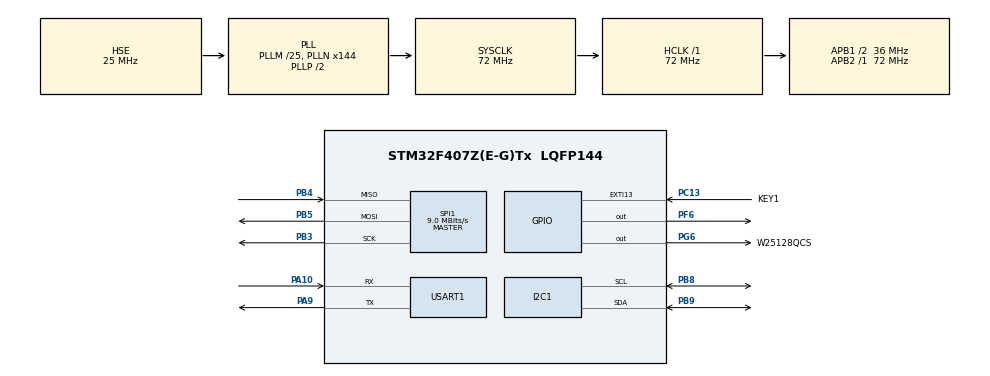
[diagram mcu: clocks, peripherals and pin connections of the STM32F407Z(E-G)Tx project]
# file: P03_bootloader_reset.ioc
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Mcu.Family=STM32F4
Mcu.Name=STM32F407Z(E-G)Tx
Mcu.Package=LQFP144
NVIC.EXTI15_10_IRQn=true\:4\:0\:true\:false\:true\:true\:true\:true
NVIC.PriorityGroup=NVIC_PRIORITYGROUP_4
NVIC.USART1_IRQn=true\:5\:0\:true\:false\:true\:true\:true\:true
PA10.Mode=Asynchronous
PA10.Signal=USART1_RX
PA13.Mode=Serial_Wire
PA13.Signal=SYS_JTMS-SWDIO
PA14.Mode=Serial_Wire
PA14.Signal=SYS_JTCK-SWCLK
PA9.Mode=Asynchronous
PA9.Signal=USART1_TX
PB3.Mode=Full_Duplex_Master
PB3.Signal=SPI1_SCK
PB4.Mode=Full_Duplex_Master
PB4.Signal=SPI1_MISO
PB5.Mode=Full_Duplex_Master
PB5.Signal=SPI1_MOSI
PB8.Mode=I2C
PB8.Signal=I2C1_SCL
PB9.Mode=I2C
PB9.Signal=I2C1_SDA
PC13-ANTI_TAMP.GPIO_Label=KEY1
PC13-ANTI_TAMP.GPIO_ModeDefaultEXTI=GPIO_MODE_IT_RISING
PC13-ANTI_TAMP.GPIO_PuPd=GPIO_PULLDOWN
PC13-ANTI_TAMP.Signal=GPXTI13
PC14-OSC32_IN.Mode=LSE-External-Oscillator
PC14-OSC32_IN.Signal=RCC_OSC32_IN
PC15-OSC32_OUT.Mode=LSE-External-Oscillator
PC15-OSC32_OUT.Signal=RCC_OSC32_OUT
PF6.GPIO_PuPd=GPIO_NOPULL
PF6.Signal=GPIO_Output
PG6.GPIO_Label=W25128QCS
PG6.GPIO_Speed=GPIO_SPEED_FREQ_HIGH
PG6.PinState=GPIO_PIN_SET
PG6.Signal=GPIO_Output
PH0-OSC_IN.Mode=HSE-External-Oscillator
PH0-OSC_IN.Signal=RCC_OSC_IN
PH1-OSC_OUT.Mode=HSE-External-Oscillator
PH1-OSC_OUT.Signal=RCC_OSC_OUT
ProjectManager.HeapSize=0x200
ProjectManager.StackSize=0x400
ProjectManager.TargetToolchain=MDK-ARM V5.32
RCC.48MHZClocksFreq_Value=36000000
RCC.AHBFreq_Value=72000000
RCC.APB1CLKDivider=RCC_HCLK_DIV2
RCC.APB1Freq_Value=36000000
RCC.APB1TimFreq_Value=72000000
RCC.APB2Freq_Value=72000000
RCC.APB2TimFreq_Value=72000000
RCC.CortexFreq_Value=72000000
RCC.HCLKFreq_Value=72000000
RCC.HSE_VALUE=25000000
RCC.HSI_VALUE=16000000
RCC.PLLM=25
RCC.PLLN=144
RCC.PLLSourceVirtual=RCC_PLLSOURCE_HSE
RCC.SYSCLKFreq_VALUE=72000000
RCC.SYSCLKSource=RCC_SYSCLKSOURCE_PLLCLK
RCC.VCOOutputFreq_Value=144000000
SPI1.BaudRatePrescaler=SPI_BAUDRATEPRESCALER_8
SPI1.CalculateBaudRate=9.0 MBits/s
SPI1.Direction=SPI_DIRECTION_2LINES
SPI1.Mode=SPI_MODE_MASTER
SPI1.VirtualType=VM_MASTER
USART1.VirtualMode=VM_ASYNC
board=custom

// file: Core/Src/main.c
/* USER CODE BEGIN Header */
/**
  ******************************************************************************
  * @file           : main.c
  * @brief          : Main program body
  ******************************************************************************
  * @attention
  *
  * Copyright (c) 2026 STMicroelectronics.
  * All rights reserved.
  *
  * This software is licensed under terms that can be found in the LICENSE file
  * in the root directory of this software component.
  * If no LICENSE file comes with this software, it is provided AS-IS.
  *
  ******************************************************************************
  */
/* USER CODE END Header */
#include "main.h"
#include "i2c.h"
#include "spi.h"
#include "usart.h"
#include "gpio.h"

/* USER CODE BEGIN Includes */
 #include "App_reset.h"
/* USER CODE END Includes */

void SystemClock_Config(void);

int main(void)
{

  /* USER CODE BEGIN 1 */

  // bootloader跳转前调用了__disable_irq()，必须在此重新开启全局中断
  __enable_irq();

  /* USER CODE END 1 */

  /* MCU Configuration--------------------------------------------------------*/

  /* Reset of all peripherals, Initializes the Flash interface and the Systick. */
  HAL_Init();

  /* Configure the system clock */
  SystemClock_Config();

  /* Initialize all configured peripherals */
  MX_GPIO_Init();
  MX_USART1_UART_Init();
  MX_I2C1_Init();
  MX_SPI1_Init();
  /* USER CODE BEGIN 2 */

  //出厂设置的默认程序
  App_bootloader_init();
  //点亮LED，表示boot loader程序正在运行
  HAL_GPIO_WritePin(GPIOF, GPIO_PIN_6, GPIO_PIN_RESET); // 红灯亮

  /* USER CODE END 2 */

  /* Infinite loop */
  /* USER CODE BEGIN WHILE */
  while (1)
  {
     //在main方法的while循环中调用的主函数，负责整个boot loader的流程控制
      App_bootlaoder_work();
    /* USER CODE END WHILE */

}}

void SystemClock_Config(void)
{
  RCC_OscInitTypeDef RCC_OscInitStruct = {0};
  RCC_ClkInitTypeDef RCC_ClkInitStruct = {0};

  /** Configure the main internal regulator output voltage
  */
  __HAL_RCC_PWR_CLK_ENABLE();
  __HAL_PWR_VOLTAGESCALING_CONFIG(PWR_REGULATOR_VOLTAGE_SCALE1);

  /** Initializes the RCC Oscillators according to the specified parameters
  * in the RCC_OscInitTypeDef structure.
  */
  RCC_OscInitStruct.OscillatorType = RCC_OSCILLATORTYPE_HSE;
  RCC_OscInitStruct.HSEState = RCC_HSE_ON;
  RCC_OscInitStruct.PLL.PLLState = RCC_PLL_ON;
  RCC_OscInitStruct.PLL.PLLSource = RCC_PLLSOURCE_HSE;
  RCC_OscInitStruct.PLL.PLLM = 25;
  RCC_OscInitStruct.PLL.PLLN = 144;
  RCC_OscInitStruct.PLL.PLLP = RCC_PLLP_DIV2;
  RCC_OscInitStruct.PLL.PLLQ = 4;
  if (HAL_RCC_OscConfig(&RCC_OscInitStruct) != HAL_OK)
  {
    Error_Handler();
  }

  /** Initializes the CPU, AHB and APB buses clocks
  */
  RCC_ClkInitStruct.ClockType = RCC_CLOCKTYPE_HCLK|RCC_CLOCKTYPE_SYSCLK
                              |RCC_CLOCKTYPE_PCLK1|RCC_CLOCKTYPE_PCLK2;
  RCC_ClkInitStruct.SYSCLKSource = RCC_SYSCLKSOURCE_PLLCLK;
  RCC_ClkInitStruct.AHBCLKDivider = RCC_SYSCLK_DIV1;
  RCC_ClkInitStruct.APB1CLKDivider = RCC_HCLK_DIV2;
  RCC_ClkInitStruct.APB2CLKDivider = RCC_HCLK_DIV1;

  if (HAL_RCC_ClockConfig(&RCC_ClkInitStruct, FLASH_LATENCY_2) != HAL_OK)
  {
    Error_Handler();
  }
}

void Error_Handler(void)
{
  __disable_irq();
  while (1)
  {
  }
}
